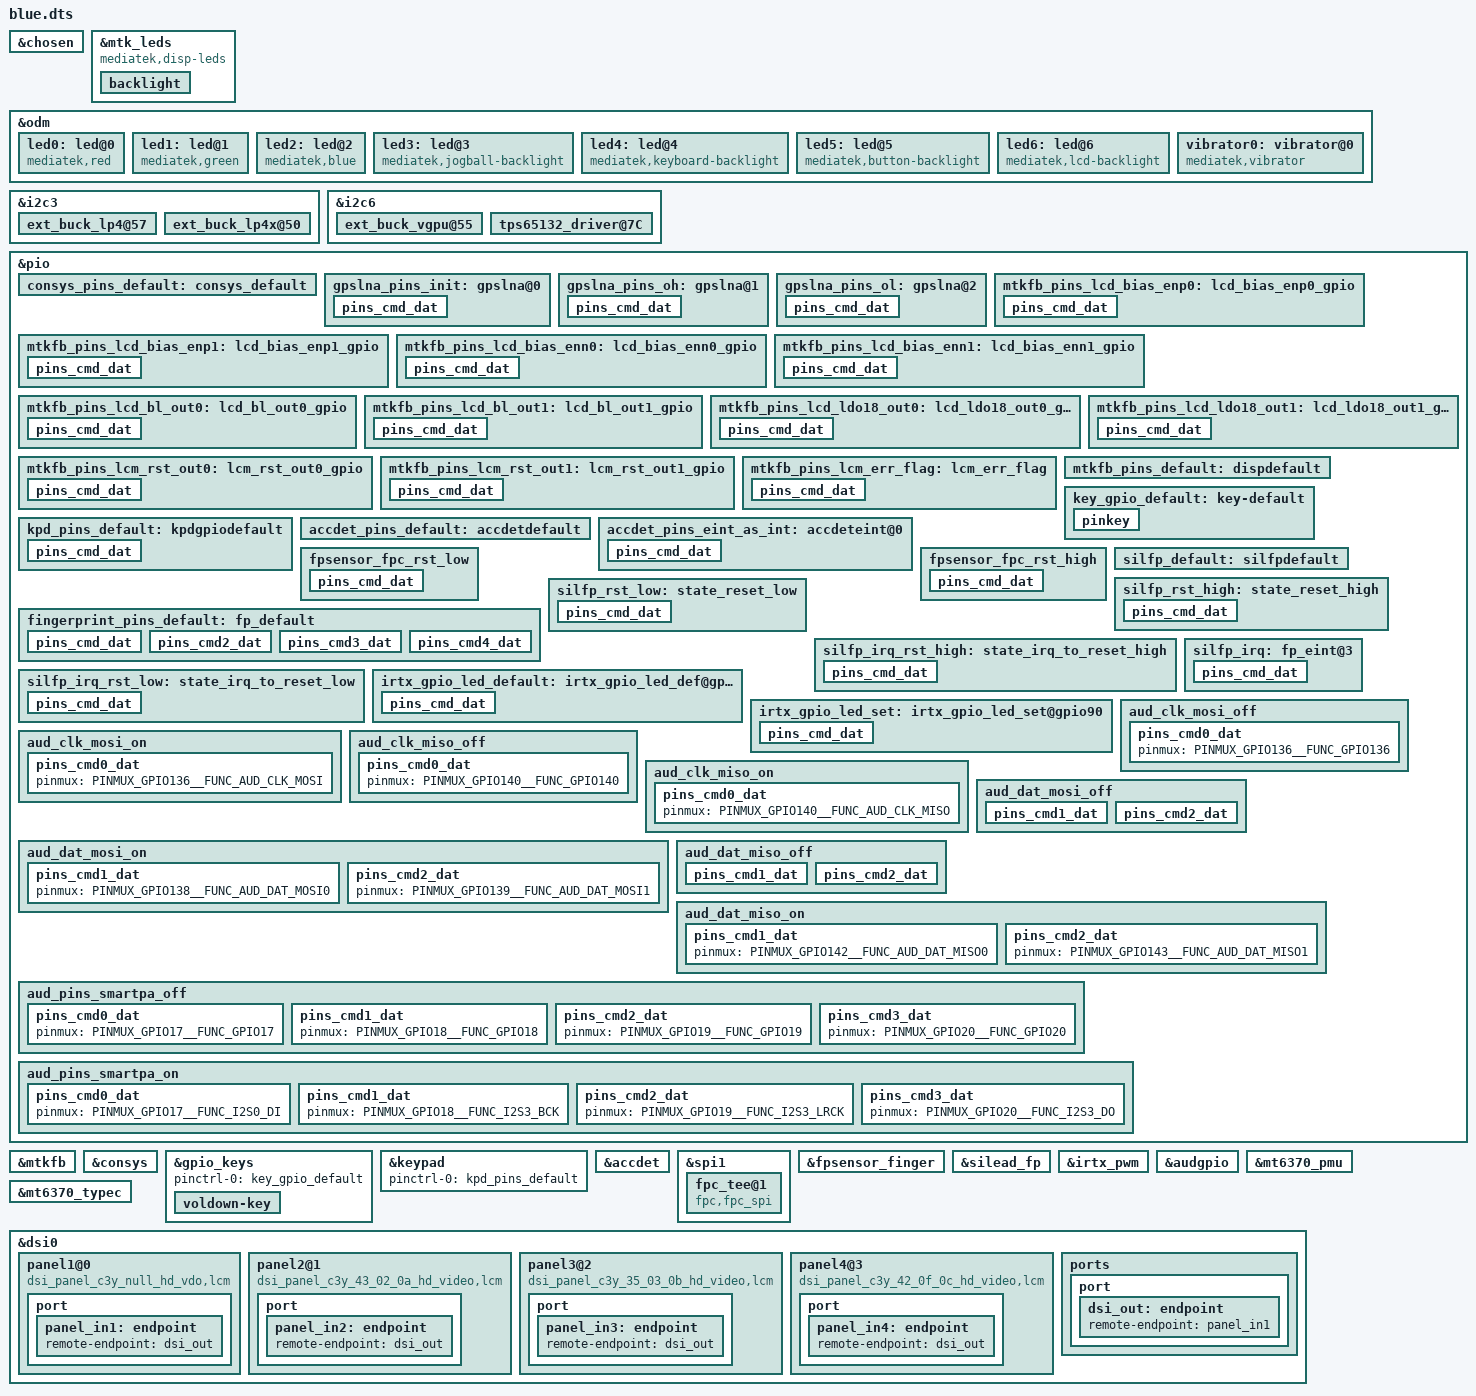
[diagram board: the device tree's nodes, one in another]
// SPDX-License-Identifier: GPL-2.0+
/*
 * Copyright (c) 2019 MediaTek Inc.
 *
 */

#include <dt-bindings/interrupt-controller/arm-gic.h>
#include <dt-bindings/interrupt-controller/irq.h>
#include <dt-bindings/pinctrl/mt6765-pinfunc.h>
#include <dt-bindings/clock/mt6765-clk.h>

/dts-v1/;
/plugin/;

/* chosen */
&chosen {

	/* fpga may has no lk, we need to specify display info here */
	/* fb buffer is reserved using this dts by memory node above */
	atag,videolfb-fb_base_h = <0x0>;
	atag,videolfb-fb_base_l = <0x5e605000>;
	atag,videolfb-islcmfound = <1>;
	/* because no lk, so lcm is not inited */
	atag,videolfb-islcm_inited = <0>;
	atag,videolfb-fps= <6000>;
	atag,videolfb-vramSize= <0x017bb000>;
	atag,videolfb-lcmname= "dsi_panel_c3y_43_02_0a_hd_video";
};

&mtk_leds {
	compatible = "mediatek,disp-leds";
	backlight {
		led_mode = <4>;
		max-brightness = <2047>;
		max-hw-brightness = <2047>;
		min-brightness = <1>;
	};
};

&odm {
	led0:led@0 {
		compatible = "mediatek,red";
		led_mode = <0>;
		data = <1>;
		pwm_config = <0 0 0 0 0>;
	};
	led1:led@1 {
		compatible = "mediatek,green";
		led_mode = <0>;
		data = <1>;
		pwm_config = <0 0 0 0 0>;
	};
	led2:led@2 {
		compatible = "mediatek,blue";
		led_mode = <0>;
		data = <1>;
		pwm_config = <0 0 0 0 0>;
	};
	led3:led@3 {
		compatible = "mediatek,jogball-backlight";
		led_mode = <0>;
		data = <1>;
		pwm_config = <0 0 0 0 0>;
	};
	led4:led@4 {
		compatible = "mediatek,keyboard-backlight";
		led_mode = <0>;
		data = <1>;
		pwm_config = <0 0 0 0 0>;
	};
	led5:led@5 {
		compatible = "mediatek,button-backlight";
		led_mode = <0>;
		data = <1>;
		pwm_config = <0 0 0 0 0>;
	};
	led6:led@6 {
		compatible = "mediatek,lcd-backlight";
		led_mode = <4>;
		data = <1>;
		pwm_config = <0 3 0 0 0>;
	};
	vibrator0:vibrator@0 {
		compatible = "mediatek,vibrator";
		vib_timer = <25>;
		vib_limit = <9>;
		vib_vol= <9>;
	};
};

&i2c3 {
	ext_buck_lp4@57 {
		regulator-name ="ext_buck_vdd2";
		regulator-min-microvolt = <300000>;
		regulator-max-microvolt = <1300000>;
		vsel_pin = <0>;
	};

	ext_buck_lp4x@50 {
		regulator-name ="ext_buck_vddq";
		regulator-min-microvolt = <300000>;
		regulator-max-microvolt = <1300000>;
		vsel_pin = <1>;
	};
};

&i2c6 {
	ext_buck_vgpu@55 {
		regulator-name ="ext_buck_vgpu";
		regulator-min-microvolt = <300000>;
		regulator-max-microvolt = <1300000>;
		vsel_pin = <2>;
	};

	tps65132_driver@7C {
		compatibel = "mediatek,I2C_LCD_BIAS";
		reg = <0x7C>;
	};
};

/* CONSYS GPIO standardization */
&pio {
	consys_pins_default: consys_default {
	};
	gpslna_pins_init: gpslna@0 {
		pins_cmd_dat {
			pinmux = <PINMUX_GPIO91__FUNC_GPIO91>;
			slew-rate = <0>;
			bias-disable;
			output-low;
		};
	};
	gpslna_pins_oh: gpslna@1 {
		pins_cmd_dat {
			pinmux = <PINMUX_GPIO91__FUNC_GPIO91>;
			slew-rate = <1>;
			output-high;
		};
	};
	gpslna_pins_ol: gpslna@2 {
		pins_cmd_dat {
			pinmux = <PINMUX_GPIO91__FUNC_GPIO91>;
			slew-rate = <1>;
			output-low;
		};
	};

mtkfb_pins_lcd_bias_enp0: lcd_bias_enp0_gpio {
				pins_cmd_dat {
					pinmux = <PINMUX_GPIO168__FUNC_GPIO168>;
					slew-rate = <1>;
					output-low;
			};
		};

	mtkfb_pins_lcd_bias_enp1: lcd_bias_enp1_gpio {
			pins_cmd_dat {
				pinmux = <PINMUX_GPIO168__FUNC_GPIO168>;
				slew-rate = <1>;
				output-high;
			};
		};

	mtkfb_pins_lcd_bias_enn0: lcd_bias_enn0_gpio {
			pins_cmd_dat {
				pinmux = <PINMUX_GPIO173__FUNC_GPIO173>;
				slew-rate = <1>;
				output-low;
			};
		};

	mtkfb_pins_lcd_bias_enn1: lcd_bias_enn1_gpio {
			pins_cmd_dat {
					pinmux = <PINMUX_GPIO173__FUNC_GPIO173>;
					slew-rate = <1>;
					output-high;
				};
		};
	mtkfb_pins_lcd_bl_out0: lcd_bl_out0_gpio {
			pins_cmd_dat {
					pinmux = <PINMUX_GPIO154__FUNC_GPIO154>;
					slew-rate = <1>;
					output-low;
				};
		};

	mtkfb_pins_lcd_bl_out1: lcd_bl_out1_gpio {
			pins_cmd_dat {
					pinmux = <PINMUX_GPIO154__FUNC_GPIO154>;
					slew-rate = <1>;
					output-high;
			};
		};

	mtkfb_pins_lcd_ldo18_out0: lcd_ldo18_out0_gpio {
			pins_cmd_dat {
					pinmux = <PINMUX_GPIO178__FUNC_GPIO178>;
					slew-rate = <1>;
					output-low;
				};
		};

	mtkfb_pins_lcd_ldo18_out1: lcd_ldo18_out1_gpio {
			pins_cmd_dat {
					pinmux = <PINMUX_GPIO178__FUNC_GPIO178>;
					slew-rate = <1>;
					output-high;
				};
		};

	mtkfb_pins_lcm_rst_out0: lcm_rst_out0_gpio {
			pins_cmd_dat {
					pinmux = <PINMUX_GPIO45__FUNC_GPIO45>;
					slew-rate = <1>;
					output-low;
				};
		};

	mtkfb_pins_lcm_rst_out1: lcm_rst_out1_gpio {
			pins_cmd_dat {
					pinmux = <PINMUX_GPIO45__FUNC_GPIO45>;
					slew-rate = <1>;
					output-high;
				};
		};
	mtkfb_pins_lcm_err_flag: lcm_err_flag {
		pins_cmd_dat {
			pinmux = <PINMUX_GPIO20__FUNC_GPIO20>;
			slew-rate = <0>;
			bias-disable;
		};
	};

	mtkfb_pins_default: dispdefault {
	};

};

&mtkfb{
	pinctrl-names = "dispdefault","lcd_bias_enp0_gpio","lcd_bias_enp1_gpio",
			"lcd_bias_enn0_gpio","lcd_bias_enn1_gpio",
			"lcd_bl_out0_gpio","lcd_bl_out1_gpio",
			"lcd_ldo18_out0_gpio","lcd_ldo18_out1_gpio",
			"lcm_rst_out0_gpio","lcm_rst_out1_gpio","err_flag_init";
	pinctrl-0 = <&mtkfb_pins_default>;
	pinctrl-1 = <&mtkfb_pins_lcd_bias_enp0>;
	pinctrl-2 = <&mtkfb_pins_lcd_bias_enp1>;
	pinctrl-3 = <&mtkfb_pins_lcd_bias_enn0>;
	pinctrl-4 = <&mtkfb_pins_lcd_bias_enn1>;
	pinctrl-5 = <&mtkfb_pins_lcd_bl_out0>;
	pinctrl-6 = <&mtkfb_pins_lcd_bl_out1>;
	pinctrl-7 = <&mtkfb_pins_lcd_ldo18_out0>;
	pinctrl-8 = <&mtkfb_pins_lcd_ldo18_out1>;
	pinctrl-9 = <&mtkfb_pins_lcm_rst_out0>;
	pinctrl-10 = <&mtkfb_pins_lcm_rst_out1>;
	pinctrl-11 = <&mtkfb_pins_lcm_err_flag>;
	status = "okay";
};

&consys {
	pinctrl-names = "default", "gps_lna_state_init",
		"gps_lna_state_oh", "gps_lna_state_ol","err_flag_init";
	pinctrl-0 = <&consys_pins_default>;
	pinctrl-1 = <&gpslna_pins_init>;
	pinctrl-2 = <&gpslna_pins_oh>;
	pinctrl-3 = <&gpslna_pins_ol>;
	pinctrl-4 = <&mtkfb_pins_lcm_err_flag>;
	status = "okay";
};
/* CONSYS end */

/* gpio_keys start */
&gpio_keys {
    status = "okay";
    pinctrl-names = "default";
    pinctrl-0 = <&key_gpio_default>;
    voldown-key {
        wakeup-source;
        debounce-interval = <20>;
        label = "Volume_Down";
        gpios = <&pio 93 1>;
        linux,code = <114>;
        linux,input-type = <1>;
    };
};

&pio{
    key_gpio_default:key-default {
        pinkey {
            pinmux = <PINMUX_GPIO93__FUNC_GPIO93>;
            input-enable;
            bias-pull-up = <MTK_PUPD_SET_R1R0_01>;
        };
    };
};
/* gpio_keys end */

&keypad {
	pinctrl-names = "default";
	pinctrl-0 = <&kpd_pins_default>;
};

&pio {
	kpd_pins_default: kpdgpiodefault {
		pins_cmd_dat {
			pinmux = <PINMUX_GPIO93__FUNC_KPCOL0>;
			bias-pull-up = <MTK_PUPD_SET_R1R0_10>;
			output-low;
			input-schmitt-enable;
		};
	};
};

/* accdet start */
&accdet {
	accdet-mic-vol = <6>;
	headset-mode-setting = <0x500 0x500 1 0x1f0 0x800 0x800 0x20 0x44>;
	accdet-plugout-debounce = <1>;
	accdet-mic-mode = <1>;
	headset-eint-level-pol = <8>;
	headset-three-key-threshold = <0 80 220 400>;
	headset-three-key-threshold-CDD = <0 121 192 600>;
	headset-four-key-threshold = <0 58 121 192 400>;
	pinctrl-names = "default", "state_eint_as_int";
	pinctrl-0 = <&accdet_pins_default>;
	pinctrl-1 = <&accdet_pins_eint_as_int>;
	status = "okay";
};
&pio {
	accdet_pins_default: accdetdefault {
	};
	accdet_pins_eint_as_int: accdeteint@0 {
		pins_cmd_dat {
			pinmux = <PINMUX_GPIO9__FUNC_GPIO9>;
			slew-rate = <0>;
			bias-disable;
		};
	};
};
/* accdet end */

/* FINGERPRINT start */
&spi1 {
	#address-cells = <1>;
	#size-cells = <0>;
	fpc_tee@1 {
		compatible = "fpc,fpc_spi";
		reg = <0>;
		fpc,enable-wakeup;
		spi-max-frequency = <10000000>;
		netlink-event = <31>;
		VFP-supply = <&mt_pmic_vldo28_ldo_reg>;
		status = "okay";
	};
};

&fpsensor_finger {
	pinctrl-names = "fpsensor_fpc_rst_low", "fpsensor_fpc_rst_high";
	pinctrl-0 = <&fpsensor_fpc_rst_low>;
	pinctrl-1 = <&fpsensor_fpc_rst_high>;
	VFP-supply = <&mt_pmic_vldo28_ldo_reg>;
	status = "okay";
};

&silead_fp {
	pinctrl-names = "default", "rst-low", "rst-high" ,
	                "irq-init", "spi-default", "irq_rst-low", "irq_rst-high";
	pinctrl-0 = <&silfp_default>;
	pinctrl-1 = <&silfp_rst_low>;
	pinctrl-2 = <&silfp_rst_high>;
	pinctrl-3 = <&silfp_irq>;
	pinctrl-4 = <&fingerprint_pins_default>;
	pinctrl-5 = <&silfp_irq_rst_low>;
	pinctrl-6 = <&silfp_irq_rst_high>;
	avdd-supply = <&mt_pmic_vldo28_ldo_reg>;
	status = "okay";
};

&pio {
	fpsensor_fpc_rst_low: fpsensor_fpc_rst_low {
		pins_cmd_dat {
			pinmux = <PINMUX_GPIO167__FUNC_GPIO167>;
			slew-rate = <1>;
			output-low;
		};
	};
	fpsensor_fpc_rst_high: fpsensor_fpc_rst_high {
		pins_cmd_dat {
			pinmux = <PINMUX_GPIO167__FUNC_GPIO167>;
			slew-rate = <1>;
			output-high;
		};
	};
};

&pio {
	fingerprint_pins_default: fp_default {
		pins_cmd_dat {
			pinmux = <PINMUX_GPIO26__FUNC_SPI1_A_CSB>;
			slew-rate = <1>;
			bias-pull-up;
		};

		pins_cmd2_dat {
			pinmux = <PINMUX_GPIO28__FUNC_SPI1_A_CLK>;
			slew-rate = <1>;
			bias-pull-down;
		};

		pins_cmd3_dat {
			pinmux = <PINMUX_GPIO25__FUNC_SPI1_A_MI>;
			slew-rate = <0>;
			bias-pull-down;
		};

		pins_cmd4_dat {
			pinmux = <PINMUX_GPIO27__FUNC_SPI1_A_MO>;
			slew-rate = <1>;
			bias-pull-down;
		};
	};
};

&pio {
	silfp_default: silfpdefault {
	};

	silfp_rst_high: state_reset_high {
		pins_cmd_dat {
			pinmux = <PINMUX_GPIO167__FUNC_GPIO167>;
			slew-rate = <1>;
			output-high;
		};
	};

	silfp_rst_low: state_reset_low {
		pins_cmd_dat {
			pinmux = <PINMUX_GPIO167__FUNC_GPIO167>;
			slew-rate = <1>;
			output-low;
		};
	};

	silfp_irq_rst_high: state_irq_to_reset_high {
		pins_cmd_dat {
			pinmux = <PINMUX_GPIO3__FUNC_GPIO3>;
			slew-rate = <1>;
			output-high;
		};
	};

	silfp_irq_rst_low: state_irq_to_reset_low {
		pins_cmd_dat {
			pinmux = <PINMUX_GPIO3__FUNC_GPIO3>;
			slew-rate = <1>;
			output-low;
		};
	};

	silfp_irq: fp_eint@3 {
		pins_cmd_dat {
			pinmux = <PINMUX_GPIO3__FUNC_GPIO3>;
			slew-rate = <0>;
			bias-pull-down = <00>;
		};
	};
};
/* FINGERPRINT end */

/* IRTX GPIO end */
&irtx_pwm {
	pinctrl-names = "irtx_gpio_led_default", "irtx_gpio_led_set";
	pinctrl-0 = <&irtx_gpio_led_default>;
	pinctrl-1 = <&irtx_gpio_led_set>;
	status = "okay";
};
&pio {
	irtx_gpio_led_default:irtx_gpio_led_def@gpio90 {
		pins_cmd_dat {
			pinmux = <PINMUX_GPIO90__FUNC_GPIO90>;
			slew-rate = <1>;
			bias-disable;
			output-low;
			input-schmitt-enable = <0>;
		};
	};

	irtx_gpio_led_set:irtx_gpio_led_set@gpio90 {
		pins_cmd_dat {
			pinmux = <PINMUX_GPIO90__FUNC_PWM0>;
			slew-rate = <1>;
			output-high;
		};
	};
};
/* IRTX GPIO Settings -End */

/* AUDIO GPIO standardization */
&audgpio {
	pinctrl-names = "aud_clk_mosi_off",
			"aud_clk_mosi_on",
			"aud_clk_miso_off",
			"aud_clk_miso_on",
			"aud_dat_mosi_off",
			"aud_dat_mosi_on",
			"aud_dat_miso_off",
			"aud_dat_miso_on",
			"aud_smartpa_off",
			"aud_smartpa_on";
	pinctrl-0 = <&aud_clk_mosi_off>;
	pinctrl-1 = <&aud_clk_mosi_on>;
	pinctrl-2 = <&aud_clk_miso_off>;
	pinctrl-3 = <&aud_clk_miso_on>;
	pinctrl-4 = <&aud_dat_mosi_off>;
	pinctrl-5 = <&aud_dat_mosi_on>;
	pinctrl-6 = <&aud_dat_miso_off>;
	pinctrl-7 = <&aud_dat_miso_on>;
	pinctrl-8 = <&aud_pins_smartpa_off>;
	pinctrl-9 = <&aud_pins_smartpa_on>;
	status = "okay";
};

&pio {
	aud_clk_mosi_off: aud_clk_mosi_off {
		pins_cmd0_dat {
			pinmux = <PINMUX_GPIO136__FUNC_GPIO136>;
		};
	};

	aud_clk_mosi_on: aud_clk_mosi_on {
		pins_cmd0_dat {
			pinmux = <PINMUX_GPIO136__FUNC_AUD_CLK_MOSI>;
		};
	};

	aud_clk_miso_off: aud_clk_miso_off {
		pins_cmd0_dat {
			pinmux = <PINMUX_GPIO140__FUNC_GPIO140>;
		};
	};

	aud_clk_miso_on: aud_clk_miso_on {
		pins_cmd0_dat {
			pinmux = <PINMUX_GPIO140__FUNC_AUD_CLK_MISO>;
		};
	};

	aud_dat_mosi_off: aud_dat_mosi_off {
		pins_cmd1_dat {
			pinmux = <PINMUX_GPIO138__FUNC_GPIO138>;
			input-enable;
			slew-rate = <0>;
			bias-disable;
		};
		pins_cmd2_dat {
			pinmux = <PINMUX_GPIO139__FUNC_GPIO139>;
			input-enable;
			slew-rate = <0>;
			bias-disable;
		};
	};

	aud_dat_mosi_on: aud_dat_mosi_on {
		pins_cmd1_dat {
			pinmux = <PINMUX_GPIO138__FUNC_AUD_DAT_MOSI0>;
		};
		pins_cmd2_dat {
			pinmux = <PINMUX_GPIO139__FUNC_AUD_DAT_MOSI1>;
		};
	};

	aud_dat_miso_off: aud_dat_miso_off {
		pins_cmd1_dat {
			pinmux = <PINMUX_GPIO142__FUNC_GPIO142>;
			input-enable;
			slew-rate = <0>;
			bias-disable;
		};
		pins_cmd2_dat {
			pinmux = <PINMUX_GPIO143__FUNC_GPIO143>;
			input-enable;
			slew-rate = <0>;
			bias-disable;
		};
	};

	aud_dat_miso_on: aud_dat_miso_on {
		pins_cmd1_dat {
			pinmux = <PINMUX_GPIO142__FUNC_AUD_DAT_MISO0>;
		};
		pins_cmd2_dat {
			pinmux = <PINMUX_GPIO143__FUNC_AUD_DAT_MISO1>;
		};
	};

	aud_pins_smartpa_off: aud_pins_smartpa_off {
		pins_cmd0_dat {
			pinmux = <PINMUX_GPIO17__FUNC_GPIO17>;
		};
		pins_cmd1_dat {
			pinmux = <PINMUX_GPIO18__FUNC_GPIO18>;
		};
		pins_cmd2_dat {
			pinmux = <PINMUX_GPIO19__FUNC_GPIO19>;
		};
		pins_cmd3_dat {
			pinmux = <PINMUX_GPIO20__FUNC_GPIO20>;
		};
	};

	aud_pins_smartpa_on: aud_pins_smartpa_on {
		pins_cmd0_dat {
			pinmux = <PINMUX_GPIO17__FUNC_I2S0_DI>;
		};
		pins_cmd1_dat {
			pinmux = <PINMUX_GPIO18__FUNC_I2S3_BCK>;
		};
		pins_cmd2_dat {
			pinmux = <PINMUX_GPIO19__FUNC_I2S3_LRCK>;
		};
		pins_cmd3_dat {
			pinmux = <PINMUX_GPIO20__FUNC_I2S3_DO>;
		};
	};
};
/* AUDIO end */

&mt6370_pmu {
	mt6370,intr_gpio_num = <11>; /* direct defined GPIO num */
	mt6370,intr_gpio = <&pio 11 0x0>;
};

&mt6370_typec {
	mt6370pd,intr_gpio_num = <41>; /* direct defined GPIO num */
	mt6370pd,intr_gpio = <&pio 41 0x0>;
};

/*
 *&mt6370_chg {
 *	bc12_sel = <1>;
 *};
 */

/* DISPSYS GPIO standardization */
&dsi0 {
	status = "okay";
	#address-cells = <1>;
	#size-cells = <0>;
	panel1@0 {
		compatible = "dsi_panel_c3y_null_hd_vdo,lcm";
		reg = <0>;
		reset-gpios = <&pio 45 0>;
		enp-gpios = <&pio 168 0>;
		enn-gpios = <&pio 173 0>;
		pinctrl-names = "default";
		port {
			panel_in1: endpoint {
				remote-endpoint = <&dsi_out>;
			};
		};
	};
	panel2@1 {
		compatible = "dsi_panel_c3y_43_02_0a_hd_video,lcm";
		reg = <1>;
		reset-gpios = <&pio 45 0>;
		enp-gpios = <&pio 168 0>;
		enn-gpios = <&pio 173 0>;
		pinctrl-names = "default";
		mi,esd-err-irq-gpio = <&pio 20 0x2002>;
		port {
			panel_in2: endpoint {
				remote-endpoint = <&dsi_out>;
			};
		};
	};
	panel3@2 {
		compatible = "dsi_panel_c3y_35_03_0b_hd_video,lcm";
		reg = <2>;
		reset-gpios = <&pio 45 0>;
		enp-gpios = <&pio 168 0>;
		enn-gpios = <&pio 173 0>;
		pinctrl-names = "default";
		mi,esd-err-irq-gpio = <&pio 20 0x2002>;
		port {
			panel_in3: endpoint {
				remote-endpoint = <&dsi_out>;
			};
		};
	};
	panel4@3 {
		compatible = "dsi_panel_c3y_42_0f_0c_hd_video,lcm";
		reg = <3>;
		reset-gpios = <&pio 45 0>;
		enp-gpios = <&pio 168 0>;
		enn-gpios = <&pio 173 0>;
		pinctrl-names = "default";
		mi,esd-err-irq-gpio = <&pio 20 0x2002>;
		port {
			panel_in4: endpoint {
				remote-endpoint = <&dsi_out>;
			};
		};
	};

	ports {
		port {
			dsi_out: endpoint {
				remote-endpoint = <&panel_in1>;
			};
		};
	};
};

#include <blue/cust.dtsi>
#include "mediatek/cust_mt6765_camera.dtsi"
//#include "mediatek/cust_mt6765_touch_1080x1920.dtsi"
#include "mediatek/touchscreen.dtsi"
#include "mediatek/cust_charger_pmu.dtsi"
#include "mediatek/foursemi-fs15xx.dtsi"
#include "mediatek/mt6765-sia8001.dtsi"
/*End of this file, DO NOT ADD ANYTHING HERE*/
